# LPC55S66_cm33_core1 register map
Vendor: nxp.com; File version: 1.0
CPU: CM33 r2p0, little endian, no MPU, no FPU, VTOR, 3 interrupt priority bits
Registers are 32-bit, read-write, reset 0x0 unless marked. A register's access mark holds for its fields unless they carry their own. Offsets are from the block's base; [hi:lo] are bit positions; {n}, {i} and the like mark numbered series.

## SDIF — SDMMC
Base 0x4009B000
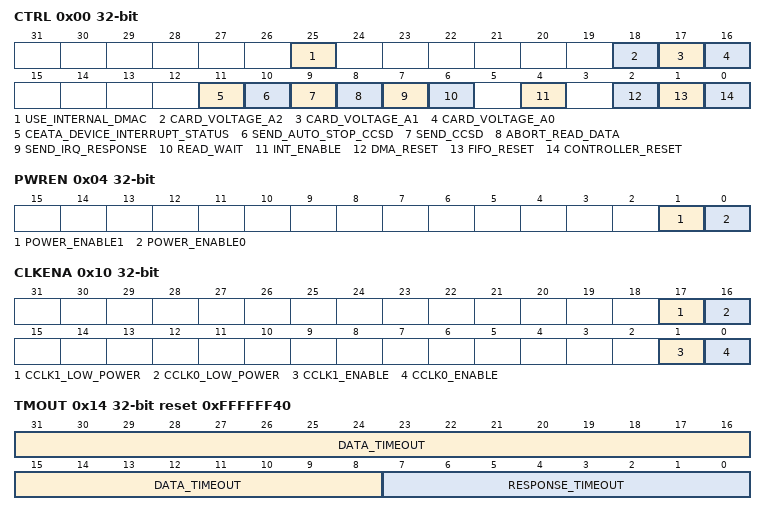
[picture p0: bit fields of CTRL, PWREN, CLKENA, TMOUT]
0x00 CTRL — Control register
  [25] USE_INTERNAL_DMAC — SD/MMC DMA use.
  [18] CARD_VOLTAGE_A2 — Controls the state of the SD_VOLT2 pin.
  [17] CARD_VOLTAGE_A1 — Controls the state of the SD_VOLT1 pin.
  [16] CARD_VOLTAGE_A0 — Controls the state of the SD_VOLT0 pin.
  [11] CEATA_DEVICE_INTERRUPT_STATUS
  [10] SEND_AUTO_STOP_CCSD
  [9] SEND_CCSD
  [8] ABORT_READ_DATA
  [7] SEND_IRQ_RESPONSE
  [6] READ_WAIT
  [4] INT_ENABLE — Global interrupt enable/disable bit.
  [2] DMA_RESET
  [1] FIFO_RESET
  [0] CONTROLLER_RESET
0x04 PWREN — Power Enable register
  [1] POWER_ENABLE1 — Power on/off switch for card 1; once power is turned on, software should wait for regulator/switch ramp-up time before trying to initialize card 1.
  [0] POWER_ENABLE0 — Power on/off switch for card 0; once power is turned on, software should wait for regulator/switch ramp-up time before trying to initialize card 0.
0x08 CLKDIV — Clock Divider register
  [7:0] CLK_DIVIDER0 — Clock divider-0 value.
0x10 CLKENA — Clock Enable register
  [17] CCLK1_LOW_POWER — Low-power control for SD card 1 clock.
  [16] CCLK0_LOW_POWER — Low-power control for SD card 0 clock.
  [1] CCLK1_ENABLE — Clock-enable control for SD card 1 clock.
  [0] CCLK0_ENABLE — Clock-enable control for SD card 0 clock.
0x14 TMOUT reset 0xFFFFFF40 — Time-out register
  [31:8] DATA_TIMEOUT — Value for card Data Read time-out; same value also used for Data Starvation by Host time-out.
  [7:0] RESPONSE_TIMEOUT — Response time-out value.
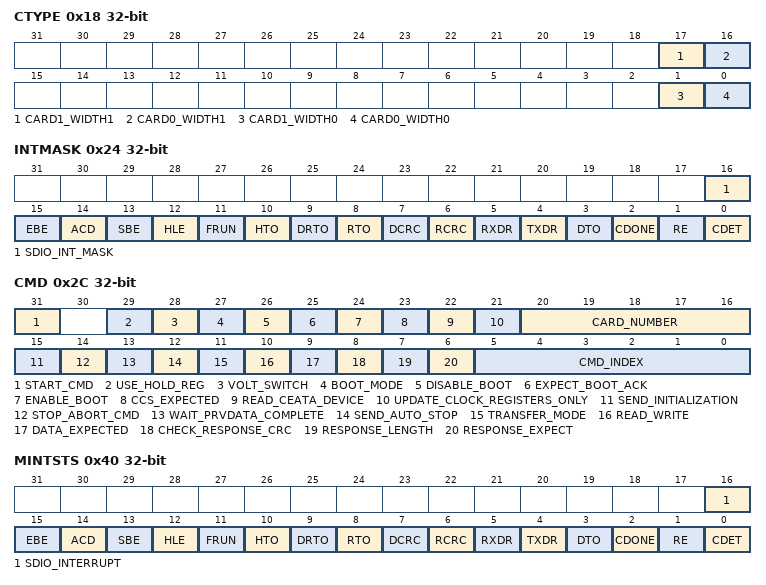
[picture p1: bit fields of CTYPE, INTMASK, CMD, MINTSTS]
0x18 CTYPE — Card Type register
  [17] CARD1_WIDTH1 — Indicates if card 1 is 8-bit: 0 - Non 8-bit mode 1 - 8-bit mode.
  [16] CARD0_WIDTH1 — Indicates if card 0 is 8-bit: 0 - Non 8-bit mode 1 - 8-bit mode.
  [1] CARD1_WIDTH0 — Indicates if card 1 is 1-bit or 4-bit: 0 - 1-bit mode 1 - 4-bit mode 1 and 4-bit modes only work when 8-bit mode in CARD1_WIDTH1 is not enabled (bit 16 in this register is set to 0).
  [0] CARD0_WIDTH0 — Indicates if card 0 is 1-bit or 4-bit: 0 - 1-bit mode 1 - 4-bit mode 1 and 4-bit modes only work when 8-bit mode in CARD0_WIDTH1 is not enabled (bit 16 in this register is set to 0).
0x1C BLKSIZ reset 0x200 — Block Size register
  [15:0] BLOCK_SIZE
0x20 BYTCNT reset 0x200 — Byte Count register
  [31:0] BYTE_COUNT — Number of bytes to be transferred; should be integer multiple of Block Size for block transfers.
0x24 INTMASK — Interrupt Mask register
  [16] SDIO_INT_MASK — Mask SDIO interrupt.
  [15] EBE — End-bit error (read)/Write no CRC.
  [14] ACD — Auto command done.
  [13] SBE — Start-bit error.
  [12] HLE — Hardware locked write error.
  [11] FRUN — FIFO underrun/overrun error.
  [10] HTO — Data starvation-by-host time-out (HTO).
  [9] DRTO — Data read time-out.
  [8] RTO — Response time-out.
  [7] DCRC — Data CRC error.
  [6] RCRC — Response CRC error.
  [5] RXDR — Receive FIFO data request.
  [4] TXDR — Transmit FIFO data request.
  [3] DTO — Data transfer over.
  [2] CDONE — Command done.
  [1] RE — Response error.
  [0] CDET — Card detect.
0x28 CMDARG — Command Argument register
  [31:0] CMD_ARG — Value indicates command argument to be passed to card.
0x2C CMD — Command register
  [31] START_CMD — Start command.
  [29] USE_HOLD_REG — Use Hold Register.
  [28] VOLT_SWITCH — Voltage switch bit.
  [27] BOOT_MODE
  [26] DISABLE_BOOT
  [25] EXPECT_BOOT_ACK — Expect Boot Acknowledge.
  [24] ENABLE_BOOT — Enable Boot - this bit should be set only for mandatory boot mode.
  [23] CCS_EXPECTED
  [22] READ_CEATA_DEVICE
  [21] UPDATE_CLOCK_REGISTERS_ONLY
  [20:16] CARD_NUMBER — Specifies the card number of SDCARD for which the current Command is being executed
    0=CARD0 (Command will be execute on SDCARD 0); 1=CARD1 (Command will be execute on SDCARD 1)
  [15] SEND_INITIALIZATION
  [14] STOP_ABORT_CMD — Stop abort command.
  [13] WAIT_PRVDATA_COMPLETE
  [12] SEND_AUTO_STOP
  [11] TRANSFER_MODE
  [10] READ_WRITE
  [9] DATA_EXPECTED
  [8] CHECK_RESPONSE_CRC
  [7] RESPONSE_LENGTH
  [6] RESPONSE_EXPECT
  [5:0] CMD_INDEX — Command index.
{0x30+4i} RESP[{i}] (i=0..3) — Response register
  [31:0] RESPONSE — Bits of response.
0x40 MINTSTS — Masked Interrupt Status register
  [16] SDIO_INTERRUPT — Interrupt from SDIO card.
  [15] EBE — End-bit error (read)/write no CRC.
  [14] ACD — Auto command done.
  [13] SBE — Start-bit error.
  [12] HLE — Hardware locked write error.
  [11] FRUN — FIFO underrun/overrun error.
  [10] HTO — Data starvation-by-host time-out (HTO).
  [9] DRTO — Data read time-out.
  [8] RTO — Response time-out.
  [7] DCRC — Data CRC error.
  [6] RCRC — Response CRC error.
  [5] RXDR — Receive FIFO data request.
  [4] TXDR — Transmit FIFO data request.
  [3] DTO — Data transfer over.
  [2] CDONE — Command done.
  [1] RE — Response error.
  [0] CDET — Card detect.
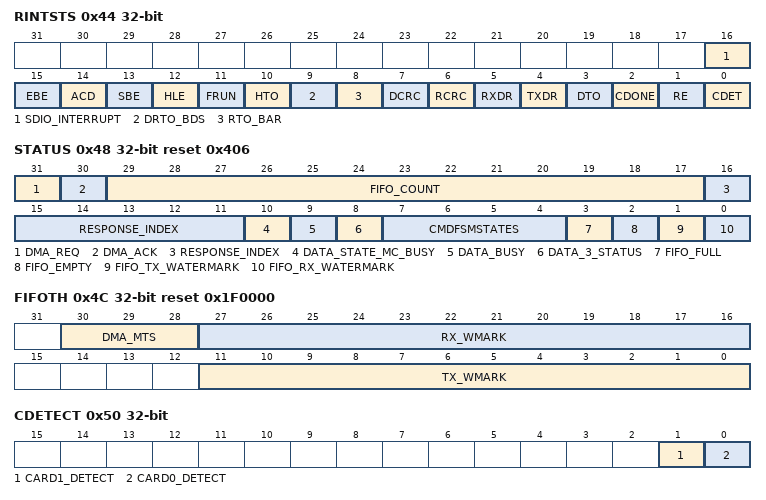
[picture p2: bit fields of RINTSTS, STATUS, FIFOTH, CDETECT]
0x44 RINTSTS — Raw Interrupt Status register
  [16] SDIO_INTERRUPT — Interrupt from SDIO card.
  [15] EBE — End-bit error (read)/write no CRC.
  [14] ACD — Auto command done.
  [13] SBE — Start-bit error.
  [12] HLE — Hardware locked write error.
  [11] FRUN — FIFO underrun/overrun error.
  [10] HTO — Data starvation-by-host time-out (HTO).
  [9] DRTO_BDS — Data read time-out (DRTO)/Boot Data Start (BDS).
  [8] RTO_BAR — Response time-out (RTO)/Boot Ack Received (BAR).
  [7] DCRC — Data CRC error.
  [6] RCRC — Response CRC error.
  [5] RXDR — Receive FIFO data request.
  [4] TXDR — Transmit FIFO data request.
  [3] DTO — Data transfer over.
  [2] CDONE — Command done.
  [1] RE — Response error.
  [0] CDET — Card detect.
0x48 STATUS reset 0x406
  [31] DMA_REQ — DMA request signal state.
  [30] DMA_ACK — DMA acknowledge signal state.
  [29:17] FIFO_COUNT — FIFO count - Number of filled locations in FIFO.
  [16:11] RESPONSE_INDEX — Index of previous response, including any auto-stop sent by core.
  [10] DATA_STATE_MC_BUSY — Data transmit or receive state-machine is busy.
  [9] DATA_BUSY — Inverted version of raw selected card_data[0] 0 - card data not busy 1 - card data busy.
  [8] DATA_3_STATUS — Raw selected card_data[3]; checks whether card is present 0 - card not present 1 - card present.
  [7:4] CMDFSMSTATES — Command FSM states: 0 - Idle 1 - Send init sequence 2 - Tx cmd start bit 3 - Tx cmd tx bit 4 - Tx cmd index + arg 5 - Tx cmd crc7 6 - Tx cmd end bit 7 - Rx resp start bit 8 - Rx resp IRQ response 9 - Rx resp tx bit 10 - Rx resp cmd idx 11 - Rx resp data 12 - Rx resp crc7 13 - Rx resp end bit 14 - Cmd path wait NCC 15 - Wait; CMD-to-response turnaround NOTE: The command FSM state is represented using 19 bits.
  [3] FIFO_FULL — FIFO is full status.
  [2] FIFO_EMPTY — FIFO is empty status.
  [1] FIFO_TX_WATERMARK — FIFO reached Transmit watermark level; not qualified with data transfer.
  [0] FIFO_RX_WATERMARK — FIFO reached Receive watermark level; not qualified with data transfer.
0x4C FIFOTH reset 0x1F0000 — FIFO Threshold Watermark register
  [30:28] DMA_MTS — Burst size of multiple transaction; should be programmed same as DW-DMA controller multiple-transaction-size SRC/DEST_MSIZE.
  [27:16] RX_WMARK — FIFO threshold watermark level when receiving data to card.
  [11:0] TX_WMARK — FIFO threshold watermark level when transmitting data to card.
0x50 CDETECT (reset mask 0x1) — Card Detect register
  [1] CARD1_DETECT, [0] CARD0_DETECT
0x54 WRTPRT — Write Protect register
  [0] WRITE_PROTECT
0x5C TCBCNT — Transferred CIU Card Byte Count register
  [31:0] TRANS_CARD_BYTE_COUNT — Number of bytes transferred by CIU unit to card.
0x60 TBBCNT — Transferred Host to BIU-FIFO Byte Count register
  [31:0] TRANS_FIFO_BYTE_COUNT — Number of bytes transferred between Host/DMA memory and BIU FIFO.
0x64 DEBNCE reset 0xFFFFFF — Debounce Count register
  [23:0] DEBOUNCE_COUNT — Number of host clocks (SD_CLK) used by debounce filter logic for card detect; typical debounce time is 5-25 ms.
0x78 RST_N reset 0x1 — Hardware Reset
  [0] CARD_RESET — Hardware reset.
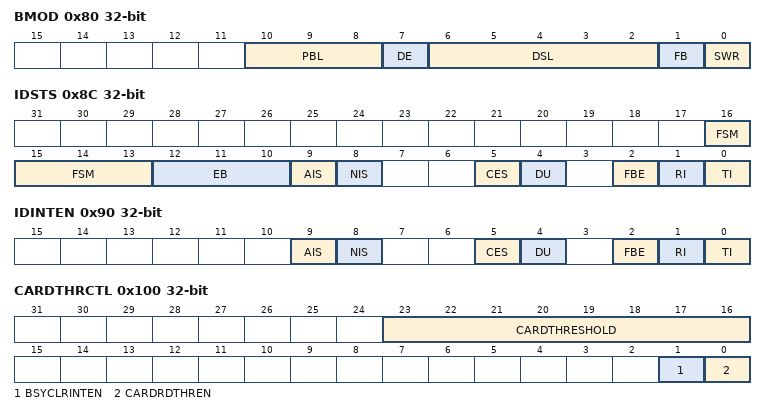
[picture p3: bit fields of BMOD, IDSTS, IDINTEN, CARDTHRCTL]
0x80 BMOD — Bus Mode register
  [10:8] PBL — Programmable Burst Length.
  [7] DE — SD/MMC DMA Enable.
  [6:2] DSL — Descriptor Skip Length.
  [1] FB — Fixed Burst.
  [0] SWR — Software Reset.
0x84 PLDMND — Poll Demand register
  [31:0] PD — Poll Demand.
0x88 DBADDR — Descriptor List Base Address register
  [31:0] SDL — Start of Descriptor List.
0x8C IDSTS — Internal DMAC Status register
  [16:13] FSM — DMAC state machine present state.
  [12:10] EB — Error Bits.
  [9] AIS — Abnormal Interrupt Summary.
  [8] NIS — Normal Interrupt Summary.
  [5] CES — Card Error Summary.
  [4] DU — Descriptor Unavailable Interrupt.
  [2] FBE — Fatal Bus Error Interrupt.
  [1] RI — Receive Interrupt.
  [0] TI — Transmit Interrupt.
0x90 IDINTEN — Internal DMAC Interrupt Enable register
  [9] AIS — Abnormal Interrupt Summary Enable.
  [8] NIS — Normal Interrupt Summary Enable.
  [5] CES — Card Error summary Interrupt Enable.
  [4] DU — Descriptor Unavailable Interrupt.
  [2] FBE — Fatal Bus Error Enable.
  [1] RI — Receive Interrupt Enable.
  [0] TI — Transmit Interrupt Enable.
0x94 DSCADDR — Current Host Descriptor Address register
  [31:0] HDA — Host Descriptor Address Pointer.
0x98 BUFADDR — Current Buffer Descriptor Address register
  [31:0] HBA — Host Buffer Address Pointer.
0x100 CARDTHRCTL — Card Threshold Control
  [23:16] CARDTHRESHOLD — Card Threshold size.
  [1] BSYCLRINTEN — Busy Clear Interrupt Enable.
  [0] CARDRDTHREN — Card Read Threshold Enable.
0x104 BACKENDPWR — Power control
  [0] BACKENDPWR — Back-end Power control for card application.
{0x200+4i} FIFO[{i}] (i=0..63) — SDIF FIFO
  [31:0] DATA — SDIF FIFO.
